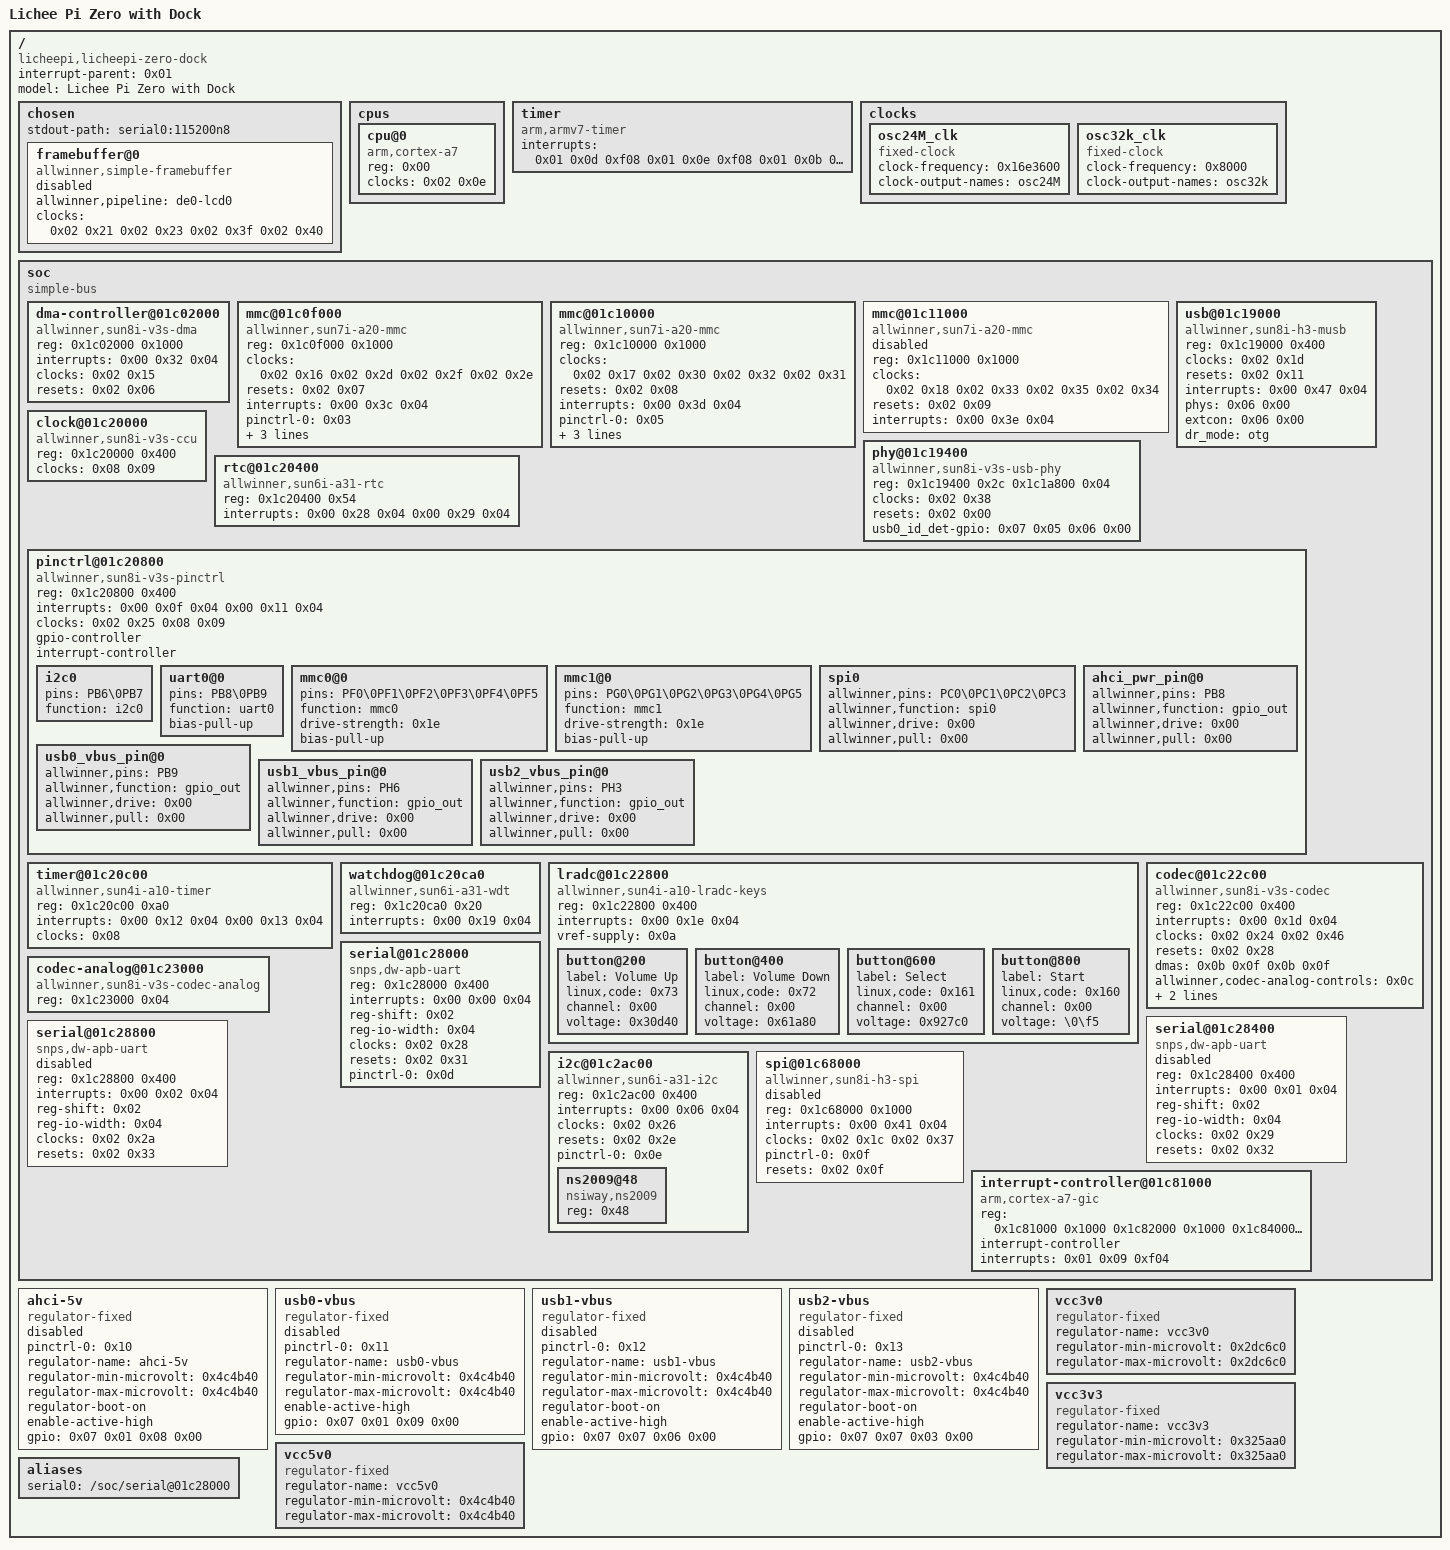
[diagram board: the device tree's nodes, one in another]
/dts-v1/;

/ {
	#address-cells = <0x01>;
	#size-cells = <0x01>;
	interrupt-parent = <0x01>;
	model = "Lichee Pi Zero with Dock";
	compatible = "licheepi,licheepi-zero-dock\0licheepi,licheepi-zero\0allwinner,sun8i-v3s";

	chosen {
		#address-cells = <0x01>;
		#size-cells = <0x01>;
		ranges;
		stdout-path = "serial0:115200n8";

		framebuffer@0 {
			compatible = "allwinner,simple-framebuffer\0simple-framebuffer";
			allwinner,pipeline = "de0-lcd0";
			clocks = <0x02 0x21 0x02 0x23 0x02 0x3f 0x02 0x40>;
			status = "disabled";
		};
	};

	cpus {
		#address-cells = <0x01>;
		#size-cells = <0x00>;

		cpu@0 {
			compatible = "arm,cortex-a7";
			device_type = "cpu";
			reg = <0x00>;
			clocks = <0x02 0x0e>;
		};
	};

	timer {
		compatible = "arm,armv7-timer";
		interrupts = <0x01 0x0d 0xf08 0x01 0x0e 0xf08 0x01 0x0b 0xf08 0x01 0x0a 0xf08>;
	};

	clocks {
		#address-cells = <0x01>;
		#size-cells = <0x01>;
		ranges;

		osc24M_clk {
			#clock-cells = <0x00>;
			compatible = "fixed-clock";
			clock-frequency = <0x16e3600>;
			clock-output-names = "osc24M";
			linux,phandle = <0x08>;
			phandle = <0x08>;
		};

		osc32k_clk {
			#clock-cells = <0x00>;
			compatible = "fixed-clock";
			clock-frequency = <0x8000>;
			clock-output-names = "osc32k";
			linux,phandle = <0x09>;
			phandle = <0x09>;
		};
	};

	soc {
		compatible = "simple-bus";
		#address-cells = <0x01>;
		#size-cells = <0x01>;
		ranges;

		dma-controller@01c02000 {
			compatible = "allwinner,sun8i-v3s-dma";
			reg = <0x1c02000 0x1000>;
			interrupts = <0x00 0x32 0x04>;
			clocks = <0x02 0x15>;
			resets = <0x02 0x06>;
			#dma-cells = <0x01>;
			linux,phandle = <0x0b>;
			phandle = <0x0b>;
		};

		mmc@01c0f000 {
			compatible = "allwinner,sun7i-a20-mmc";
			reg = <0x1c0f000 0x1000>;
			clocks = <0x02 0x16 0x02 0x2d 0x02 0x2f 0x02 0x2e>;
			clock-names = "ahb\0mmc\0output\0sample";
			resets = <0x02 0x07>;
			reset-names = "ahb";
			interrupts = <0x00 0x3c 0x04>;
			status = "okay";
			#address-cells = <0x01>;
			#size-cells = <0x00>;
			pinctrl-0 = <0x03>;
			pinctrl-names = "default";
			broken-cd;
			bus-width = <0x04>;
			vmmc-supply = <0x04>;
		};

		mmc@01c10000 {
			compatible = "allwinner,sun7i-a20-mmc";
			reg = <0x1c10000 0x1000>;
			clocks = <0x02 0x17 0x02 0x30 0x02 0x32 0x02 0x31>;
			clock-names = "ahb\0mmc\0output\0sample";
			resets = <0x02 0x08>;
			reset-names = "ahb";
			interrupts = <0x00 0x3d 0x04>;
			status = "okay";
			#address-cells = <0x01>;
			#size-cells = <0x00>;
			pinctrl-0 = <0x05>;
			pinctrl-names = "default";
			broken-cd;
			bus-width = <0x04>;
			vmmc-supply = <0x04>;
		};

		mmc@01c11000 {
			compatible = "allwinner,sun7i-a20-mmc";
			reg = <0x1c11000 0x1000>;
			clocks = <0x02 0x18 0x02 0x33 0x02 0x35 0x02 0x34>;
			clock-names = "ahb\0mmc\0output\0sample";
			resets = <0x02 0x09>;
			reset-names = "ahb";
			interrupts = <0x00 0x3e 0x04>;
			status = "disabled";
			#address-cells = <0x01>;
			#size-cells = <0x00>;
		};

		usb@01c19000 {
			compatible = "allwinner,sun8i-h3-musb";
			reg = <0x1c19000 0x400>;
			clocks = <0x02 0x1d>;
			resets = <0x02 0x11>;
			interrupts = <0x00 0x47 0x04>;
			interrupt-names = "mc";
			phys = <0x06 0x00>;
			phy-names = "usb";
			extcon = <0x06 0x00>;
			status = "okay";
			dr_mode = "otg";
		};

		phy@01c19400 {
			compatible = "allwinner,sun8i-v3s-usb-phy";
			reg = <0x1c19400 0x2c 0x1c1a800 0x04>;
			reg-names = "phy_ctrl\0pmu0";
			clocks = <0x02 0x38>;
			clock-names = "usb0_phy";
			resets = <0x02 0x00>;
			reset-names = "usb0_reset";
			status = "okay";
			#phy-cells = <0x01>;
			usb0_id_det-gpio = <0x07 0x05 0x06 0x00>;
			linux,phandle = <0x06>;
			phandle = <0x06>;
		};

		clock@01c20000 {
			compatible = "allwinner,sun8i-v3s-ccu";
			reg = <0x1c20000 0x400>;
			clocks = <0x08 0x09>;
			clock-names = "hosc\0losc";
			#clock-cells = <0x01>;
			#reset-cells = <0x01>;
			linux,phandle = <0x02>;
			phandle = <0x02>;
		};

		rtc@01c20400 {
			compatible = "allwinner,sun6i-a31-rtc";
			reg = <0x1c20400 0x54>;
			interrupts = <0x00 0x28 0x04 0x00 0x29 0x04>;
		};

		pinctrl@01c20800 {
			compatible = "allwinner,sun8i-v3s-pinctrl";
			reg = <0x1c20800 0x400>;
			interrupts = <0x00 0x0f 0x04 0x00 0x11 0x04>;
			clocks = <0x02 0x25 0x08 0x09>;
			clock-names = "apb\0hosc\0losc";
			gpio-controller;
			#gpio-cells = <0x03>;
			interrupt-controller;
			#interrupt-cells = <0x03>;
			linux,phandle = <0x07>;
			phandle = <0x07>;

			i2c0 {
				pins = "PB6\0PB7";
				function = "i2c0";
				linux,phandle = <0x0e>;
				phandle = <0x0e>;
			};

			uart0@0 {
				pins = "PB8\0PB9";
				function = "uart0";
				bias-pull-up;
				linux,phandle = <0x0d>;
				phandle = <0x0d>;
			};

			mmc0@0 {
				pins = "PF0\0PF1\0PF2\0PF3\0PF4\0PF5";
				function = "mmc0";
				drive-strength = <0x1e>;
				bias-pull-up;
				linux,phandle = <0x03>;
				phandle = <0x03>;
			};

			mmc1@0 {
				pins = "PG0\0PG1\0PG2\0PG3\0PG4\0PG5";
				function = "mmc1";
				drive-strength = <0x1e>;
				bias-pull-up;
				linux,phandle = <0x05>;
				phandle = <0x05>;
			};

			spi0 {
				allwinner,pins = "PC0\0PC1\0PC2\0PC3";
				allwinner,function = "spi0";
				allwinner,drive = <0x00>;
				allwinner,pull = <0x00>;
				linux,phandle = <0x0f>;
				phandle = <0x0f>;
			};

			ahci_pwr_pin@0 {
				allwinner,pins = "PB8";
				allwinner,function = "gpio_out";
				allwinner,drive = <0x00>;
				allwinner,pull = <0x00>;
				linux,phandle = <0x10>;
				phandle = <0x10>;
			};

			usb0_vbus_pin@0 {
				allwinner,pins = "PB9";
				allwinner,function = "gpio_out";
				allwinner,drive = <0x00>;
				allwinner,pull = <0x00>;
				linux,phandle = <0x11>;
				phandle = <0x11>;
			};

			usb1_vbus_pin@0 {
				allwinner,pins = "PH6";
				allwinner,function = "gpio_out";
				allwinner,drive = <0x00>;
				allwinner,pull = <0x00>;
				linux,phandle = <0x12>;
				phandle = <0x12>;
			};

			usb2_vbus_pin@0 {
				allwinner,pins = "PH3";
				allwinner,function = "gpio_out";
				allwinner,drive = <0x00>;
				allwinner,pull = <0x00>;
				linux,phandle = <0x13>;
				phandle = <0x13>;
			};
		};

		timer@01c20c00 {
			compatible = "allwinner,sun4i-a10-timer";
			reg = <0x1c20c00 0xa0>;
			interrupts = <0x00 0x12 0x04 0x00 0x13 0x04>;
			clocks = <0x08>;
		};

		watchdog@01c20ca0 {
			compatible = "allwinner,sun6i-a31-wdt";
			reg = <0x1c20ca0 0x20>;
			interrupts = <0x00 0x19 0x04>;
		};

		lradc@01c22800 {
			compatible = "allwinner,sun4i-a10-lradc-keys";
			reg = <0x1c22800 0x400>;
			interrupts = <0x00 0x1e 0x04>;
			status = "okay";
			vref-supply = <0x0a>;

			button@200 {
				label = "Volume Up";
				linux,code = <0x73>;
				channel = <0x00>;
				voltage = <0x30d40>;
			};

			button@400 {
				label = "Volume Down";
				linux,code = <0x72>;
				channel = <0x00>;
				voltage = <0x61a80>;
			};

			button@600 {
				label = "Select";
				linux,code = <0x161>;
				channel = <0x00>;
				voltage = <0x927c0>;
			};

			button@800 {
				label = "Start";
				linux,code = <0x160>;
				channel = <0x00>;
				voltage = "\0\f5";
			};
		};

		codec@01c22c00 {
			#sound-dai-cells = <0x00>;
			compatible = "allwinner,sun8i-v3s-codec";
			reg = <0x1c22c00 0x400>;
			interrupts = <0x00 0x1d 0x04>;
			clocks = <0x02 0x24 0x02 0x46>;
			clock-names = "apb\0codec";
			resets = <0x02 0x28>;
			dmas = <0x0b 0x0f 0x0b 0x0f>;
			dma-names = "rx\0tx";
			allwinner,codec-analog-controls = <0x0c>;
			status = "okay";
			allwinner,audio-routing = "Headphone\0HP\0Headphone\0HPCOM\0MIC1\0Mic\0Mic\0HBIAS";
		};

		codec-analog@01c23000 {
			compatible = "allwinner,sun8i-v3s-codec-analog";
			reg = <0x1c23000 0x04>;
			linux,phandle = <0x0c>;
			phandle = <0x0c>;
		};

		serial@01c28000 {
			compatible = "snps,dw-apb-uart";
			reg = <0x1c28000 0x400>;
			interrupts = <0x00 0x00 0x04>;
			reg-shift = <0x02>;
			reg-io-width = <0x04>;
			clocks = <0x02 0x28>;
			resets = <0x02 0x31>;
			status = "okay";
			pinctrl-0 = <0x0d>;
			pinctrl-names = "default";
		};

		serial@01c28400 {
			compatible = "snps,dw-apb-uart";
			reg = <0x1c28400 0x400>;
			interrupts = <0x00 0x01 0x04>;
			reg-shift = <0x02>;
			reg-io-width = <0x04>;
			clocks = <0x02 0x29>;
			resets = <0x02 0x32>;
			status = "disabled";
		};

		serial@01c28800 {
			compatible = "snps,dw-apb-uart";
			reg = <0x1c28800 0x400>;
			interrupts = <0x00 0x02 0x04>;
			reg-shift = <0x02>;
			reg-io-width = <0x04>;
			clocks = <0x02 0x2a>;
			resets = <0x02 0x33>;
			status = "disabled";
		};

		i2c@01c2ac00 {
			compatible = "allwinner,sun6i-a31-i2c";
			reg = <0x1c2ac00 0x400>;
			interrupts = <0x00 0x06 0x04>;
			clocks = <0x02 0x26>;
			resets = <0x02 0x2e>;
			pinctrl-names = "default";
			pinctrl-0 = <0x0e>;
			status = "okay";
			#address-cells = <0x01>;
			#size-cells = <0x00>;

			ns2009@48 {
				compatible = "nsiway,ns2009";
				reg = <0x48>;
			};
		};

		spi@01c68000 {
			compatible = "allwinner,sun8i-h3-spi";
			reg = <0x1c68000 0x1000>;
			interrupts = <0x00 0x41 0x04>;
			clocks = <0x02 0x1c 0x02 0x37>;
			clock-names = "ahb\0mod";
			pinctrl-names = "default";
			pinctrl-0 = <0x0f>;
			resets = <0x02 0x0f>;
			status = "disabled";
			#address-cells = <0x01>;
			#size-cells = <0x00>;
		};

		interrupt-controller@01c81000 {
			compatible = "arm,cortex-a7-gic\0arm,cortex-a15-gic";
			reg = <0x1c81000 0x1000 0x1c82000 0x1000 0x1c84000 0x2000 0x1c86000 0x2000>;
			interrupt-controller;
			#interrupt-cells = <0x03>;
			interrupts = <0x01 0x09 0xf04>;
			linux,phandle = <0x01>;
			phandle = <0x01>;
		};
	};

	ahci-5v {
		compatible = "regulator-fixed";
		pinctrl-names = "default";
		pinctrl-0 = <0x10>;
		regulator-name = "ahci-5v";
		regulator-min-microvolt = <0x4c4b40>;
		regulator-max-microvolt = <0x4c4b40>;
		regulator-boot-on;
		enable-active-high;
		gpio = <0x07 0x01 0x08 0x00>;
		status = "disabled";
	};

	usb0-vbus {
		compatible = "regulator-fixed";
		pinctrl-names = "default";
		pinctrl-0 = <0x11>;
		regulator-name = "usb0-vbus";
		regulator-min-microvolt = <0x4c4b40>;
		regulator-max-microvolt = <0x4c4b40>;
		enable-active-high;
		gpio = <0x07 0x01 0x09 0x00>;
		status = "disabled";
	};

	usb1-vbus {
		compatible = "regulator-fixed";
		pinctrl-names = "default";
		pinctrl-0 = <0x12>;
		regulator-name = "usb1-vbus";
		regulator-min-microvolt = <0x4c4b40>;
		regulator-max-microvolt = <0x4c4b40>;
		regulator-boot-on;
		enable-active-high;
		gpio = <0x07 0x07 0x06 0x00>;
		status = "disabled";
	};

	usb2-vbus {
		compatible = "regulator-fixed";
		pinctrl-names = "default";
		pinctrl-0 = <0x13>;
		regulator-name = "usb2-vbus";
		regulator-min-microvolt = <0x4c4b40>;
		regulator-max-microvolt = <0x4c4b40>;
		regulator-boot-on;
		enable-active-high;
		gpio = <0x07 0x07 0x03 0x00>;
		status = "disabled";
	};

	vcc3v0 {
		compatible = "regulator-fixed";
		regulator-name = "vcc3v0";
		regulator-min-microvolt = <0x2dc6c0>;
		regulator-max-microvolt = <0x2dc6c0>;
		linux,phandle = <0x0a>;
		phandle = <0x0a>;
	};

	vcc3v3 {
		compatible = "regulator-fixed";
		regulator-name = "vcc3v3";
		regulator-min-microvolt = <0x325aa0>;
		regulator-max-microvolt = <0x325aa0>;
		linux,phandle = <0x04>;
		phandle = <0x04>;
	};

	vcc5v0 {
		compatible = "regulator-fixed";
		regulator-name = "vcc5v0";
		regulator-min-microvolt = <0x4c4b40>;
		regulator-max-microvolt = <0x4c4b40>;
	};

	aliases {
		serial0 = "/soc/serial@01c28000";
	};
};
